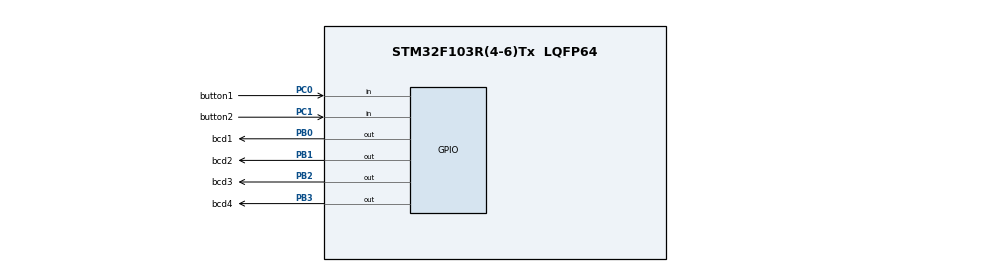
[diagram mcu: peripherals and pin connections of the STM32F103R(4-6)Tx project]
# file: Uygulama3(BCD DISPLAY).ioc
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Mcu.Family=STM32F1
Mcu.Name=STM32F103R(4-6)Tx
Mcu.Package=LQFP64
NVIC.PriorityGroup=NVIC_PRIORITYGROUP_4
PB0.GPIO_Label=bcd1
PB0.GPIO_Speed=GPIO_SPEED_FREQ_MEDIUM
PB0.Signal=GPIO_Output
PB1.GPIO_Label=bcd2
PB1.GPIO_Speed=GPIO_SPEED_FREQ_MEDIUM
PB1.Signal=GPIO_Output
PB2.GPIO_Label=bcd3
PB2.GPIO_Speed=GPIO_SPEED_FREQ_MEDIUM
PB2.Signal=GPIO_Output
PB3.GPIO_Label=bcd4
PB3.GPIO_Speed=GPIO_SPEED_FREQ_MEDIUM
PB3.Signal=GPIO_Output
PC0.GPIO_Label=button1
PC0.GPIO_PuPd=GPIO_PULLDOWN
PC0.Signal=GPIO_Input
PC1.GPIO_Label=button2
PC1.GPIO_PuPd=GPIO_PULLDOWN
PC1.Signal=GPIO_Input
ProjectManager.HeapSize=0x200
ProjectManager.StackSize=0x400
ProjectManager.TargetToolchain=MDK-ARM V5.27
RCC.APB1Freq_Value=8000000
RCC.APB2Freq_Value=8000000
VP_SYS_VS_ND.Mode=No_Debug
board=custom

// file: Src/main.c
/* USER CODE BEGIN Header */
/**
  ******************************************************************************
  * @file           : main.c
  * @brief          : Main program body
  ******************************************************************************
  * @attention
  *
  * <h2><center>&copy; Copyright (c) 2020 STMicroelectronics.
  * All rights reserved.</center></h2>
  *
  * This software component is licensed by ST under BSD 3-Clause license,
  * the "License"; You may not use this file except in compliance with the
  * License. You may obtain a copy of the License at:
  *                        opensource.org/licenses/BSD-3-Clause
  *
  ******************************************************************************
  */
/* USER CODE END Header */

#include "main.h"

/* USER CODE BEGIN PV */
uint16_t number=0;
uint16_t button1State=0;
uint16_t button2State=0;

/* USER CODE END PV */

void SystemClock_Config(void);
static void MX_GPIO_Init(void);

int main(void)
{

  /* MCU Configuration--------------------------------------------------------*/

  /* Reset of all peripherals, Initializes the Flash interface and the Systick. */
  HAL_Init();

  /* Configure the system clock */
  SystemClock_Config();

  /* Initialize all configured peripherals */
  MX_GPIO_Init();

  /* Infinite loop */
  while (1)
  {

    /* USER CODE BEGIN 3 */
		button1State=HAL_GPIO_ReadPin(button1_GPIO_Port,button1_Pin);
		button2State=HAL_GPIO_ReadPin(button2_GPIO_Port,button2_Pin);

		if(button1State){
			if(number!=9){
				number++;
			}
		}
		if(button2State){
			if(number>0){
				number--;
			}
		}

		GPIOB->ODR=number;
		HAL_Delay(200);
//		HAL_Delay(500);
//		number++;
//		if(number>9){
//			number=0;
//
//		}
  }
  /* USER CODE END 3 */
}

void SystemClock_Config(void)
{
  RCC_OscInitTypeDef RCC_OscInitStruct = {0};
  RCC_ClkInitTypeDef RCC_ClkInitStruct = {0};

  /** Initializes the CPU, AHB and APB busses clocks
  */
  RCC_OscInitStruct.OscillatorType = RCC_OSCILLATORTYPE_HSI;
  RCC_OscInitStruct.HSIState = RCC_HSI_ON;
  RCC_OscInitStruct.HSICalibrationValue = RCC_HSICALIBRATION_DEFAULT;
  RCC_OscInitStruct.PLL.PLLState = RCC_PLL_NONE;
  if (HAL_RCC_OscConfig(&RCC_OscInitStruct) != HAL_OK)
  {
    Error_Handler();
  }
  /** Initializes the CPU, AHB and APB busses clocks
  */
  RCC_ClkInitStruct.ClockType = RCC_CLOCKTYPE_HCLK|RCC_CLOCKTYPE_SYSCLK
                              |RCC_CLOCKTYPE_PCLK1|RCC_CLOCKTYPE_PCLK2;
  RCC_ClkInitStruct.SYSCLKSource = RCC_SYSCLKSOURCE_HSI;
  RCC_ClkInitStruct.AHBCLKDivider = RCC_SYSCLK_DIV1;
  RCC_ClkInitStruct.APB1CLKDivider = RCC_HCLK_DIV1;
  RCC_ClkInitStruct.APB2CLKDivider = RCC_HCLK_DIV1;

  if (HAL_RCC_ClockConfig(&RCC_ClkInitStruct, FLASH_LATENCY_0) != HAL_OK)
  {
    Error_Handler();
  }
}

static void MX_GPIO_Init(void)
{
  GPIO_InitTypeDef GPIO_InitStruct = {0};

  /* GPIO Ports Clock Enable */
  __HAL_RCC_GPIOC_CLK_ENABLE();
  __HAL_RCC_GPIOB_CLK_ENABLE();

  /*Configure GPIO pin Output Level */
  HAL_GPIO_WritePin(GPIOB, bcd1_Pin|bcd2_Pin|bcd3_Pin|bcd4_Pin, GPIO_PIN_RESET);

  /*Configure GPIO pins : button1_Pin button2_Pin */
  GPIO_InitStruct.Pin = button1_Pin|button2_Pin;
  GPIO_InitStruct.Mode = GPIO_MODE_INPUT;
  GPIO_InitStruct.Pull = GPIO_PULLDOWN;
  HAL_GPIO_Init(GPIOC, &GPIO_InitStruct);

  /*Configure GPIO pins : bcd1_Pin bcd2_Pin bcd3_Pin bcd4_Pin */
  GPIO_InitStruct.Pin = bcd1_Pin|bcd2_Pin|bcd3_Pin|bcd4_Pin;
  GPIO_InitStruct.Mode = GPIO_MODE_OUTPUT_PP;
  GPIO_InitStruct.Pull = GPIO_NOPULL;
  GPIO_InitStruct.Speed = GPIO_SPEED_FREQ_MEDIUM;
  HAL_GPIO_Init(GPIOB, &GPIO_InitStruct);

}

void Error_Handler(void)
{
}

/************************ (C) COPYRIGHT STMicroelectronics *****END OF FILE****/
